# ESP32-H21 register map
Vendor: ESPRESSIF SYSTEMS (SHANGHAI) CO., LTD.; Series: ESP32 H-Series; File version: 1
CPU: RV32IMAC r0p0, little endian, no MPU, no FPU, 0 interrupt priority bits
Address unit: 32 bits
Registers are 32-bit, read-write, reset 0x0 unless marked. A register's access mark holds for its fields unless they carry their own. Offsets are from the block's base; [hi:lo] are bit positions; {n}, {i} and the like mark numbered series.

## LP_AON — LP_AON Peripheral
Base 0x600B1000
{0x0+4i} STORE{i} (i=0..9) — need_des
  [31:0] LP_AON_STORE{i}
0x28 GPIO_MUX — need_des
  [7:0] SEL
0x2C GPIO_HOLD0 — need_des
0x30 GPIO_HOLD1 — need_des
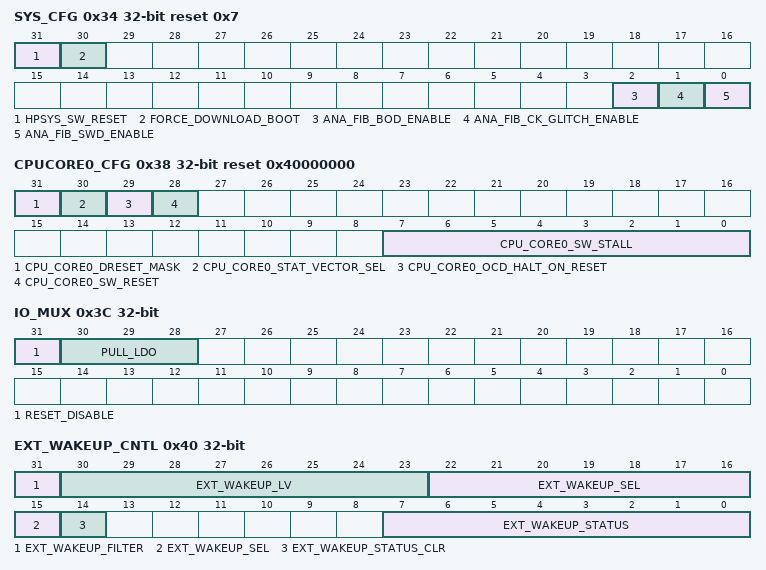
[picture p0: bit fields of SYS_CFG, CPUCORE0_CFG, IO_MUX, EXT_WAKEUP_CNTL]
0x34 SYS_CFG access per field reset 0x7 — need_des
  [31] HPSYS_SW_RESET wo — need_des
  [30] FORCE_DOWNLOAD_BOOT rw — need_des
  [2] ANA_FIB_BOD_ENABLE ro — need_des
  [1] ANA_FIB_CK_GLITCH_ENABLE ro — need_des
  [0] ANA_FIB_SWD_ENABLE ro — need_des
0x38 CPUCORE0_CFG access per field reset 0x40000000 — need_des
  [31] CPU_CORE0_DRESET_MASK rw — need_des
  [30] CPU_CORE0_STAT_VECTOR_SEL rw — need_des
  [29] CPU_CORE0_OCD_HALT_ON_RESET rw — need_des
  [28] CPU_CORE0_SW_RESET wo — need_des
  [7:0] CPU_CORE0_SW_STALL rw — need_des
0x3C IO_MUX — need_des
  [31] RESET_DISABLE — need_des
  [30:28] PULL_LDO — need_des
0x40 EXT_WAKEUP_CNTL access per field — need_des
  [31] EXT_WAKEUP_FILTER rw — need_des
  [30:23] EXT_WAKEUP_LV rw — need_des
  [22:15] EXT_WAKEUP_SEL rw — need_des
  [14] EXT_WAKEUP_STATUS_CLR wo — need_des
  [7:0] EXT_WAKEUP_STATUS ro — need_des
0x44 USB — need_des
  [31] RESET_DISABLE
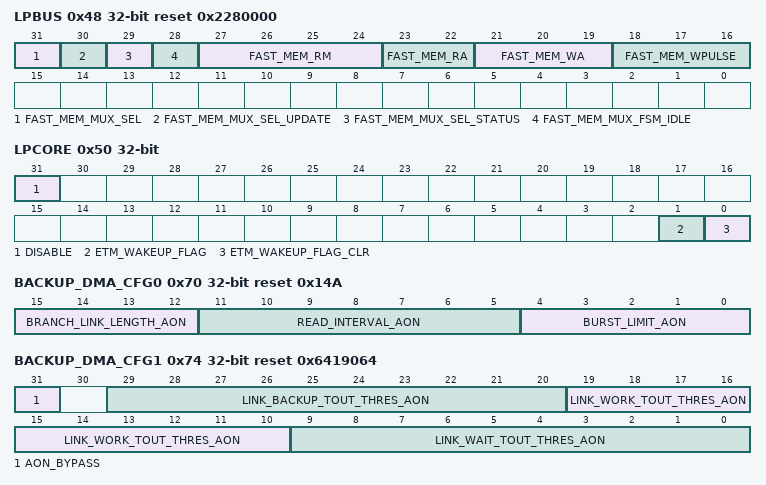
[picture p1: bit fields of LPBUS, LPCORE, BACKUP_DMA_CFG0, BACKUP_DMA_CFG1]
0x48 LPBUS access per field reset 0x2280000 — need_des
  [31] FAST_MEM_MUX_SEL ro — reserved
  [30] FAST_MEM_MUX_SEL_UPDATE ro — reserved
  [29] FAST_MEM_MUX_SEL_STATUS ro — reserved
  [28] FAST_MEM_MUX_FSM_IDLE ro — reserved
  [27:24] FAST_MEM_RM rw — This field controls fast memory RM parameter. 0b0011 for 1.1V operating Voltage, 0b0010 for 1.0V, 0b0000 for 0.9V.
  [23:22] FAST_MEM_RA rw — This field controls fast memory RA parameter. 0b00 for 1.1V/1.0V operating Voltage, 0b01 for 0.9V.
  [21:19] FAST_MEM_WA rw — This field controls fast memory WA parameter. 0b100 for 1.1V operating Voltage, 0b101 for 1.0V, 0b110 for 0.9V.
  [18:16] FAST_MEM_WPULSE rw — This field controls fast memory WPULSE parameter. 0b000 for 1.1V/1.0V/0.9V operating Voltage.
0x4C SDIO_ACTIVE reset 0x2800000 — need_des
  [31:22] SDIO_ACT_DNUM
0x50 LPCORE access per field — need_des
  [31] DISABLE rw — need_des
  [1] ETM_WAKEUP_FLAG rw — need_des
  [0] ETM_WAKEUP_FLAG_CLR wo — need_des
0x54 SAR_CCT — need_des
  [31:29] SAR2_PWDET_CCT
0x58 JTAG_SEL reset 0x80000000 — need_des
  [31] SOFT — If strapping_sel_jtag feature is disabled by efuse, and if neither pad_jtag or usb_jtag is disabled by efuse, this field determines which one jtag between usb_jtag and pad_jtag will be used. 1'b1(default): usb_jtag, 1'b0: pad_jtag.
0x70 BACKUP_DMA_CFG0 reset 0x14A — configure regdma always on register
  [15:12] BRANCH_LINK_LENGTH_AON — Set this field to configure link address.
  [11:5] READ_INTERVAL_AON — Set this field to configure read registers' interval time in reading mode.
  [4:0] BURST_LIMIT_AON — Set this field to configure max value of burst in signle transfer.
0x74 BACKUP_DMA_CFG1 reset 0x6419064 — configure regdma always on register
  [31] AON_BYPASS — reserved
  [29:20] LINK_BACKUP_TOUT_THRES_AON — Set this field to configure maximum waiting time in backup mode.
  [19:10] LINK_WORK_TOUT_THRES_AON — Set this field to configure maximum waiting time in waiting mode.
  [9:0] LINK_WAIT_TOUT_THRES_AON — Set this field to configure the number of consecutive links of link list.
0x78 BACKUP_DMA_CFG2 — configure regdma always on register
  [31:0] LINK_ADDR_AON — Set this field to configure link address.
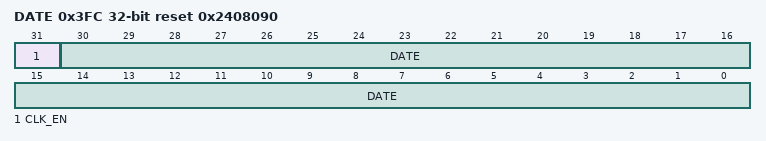
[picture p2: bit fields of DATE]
0x3FC DATE reset 0x2408090 — need_des
  [31] CLK_EN — need_des
  [30:0] DATE — need_des

## LP_APM — Low-power Access Permission Management Controller
Base 0x600B3800
0x00 REGION_FILTER_EN reset 0x1 — Region filter enable register
  [1:0] REGION_FILTER_EN — Region filter enable
0x04 REGION0_ADDR_START — Region address register
  [31:0] REGION0_ADDR_START — Start address of region0
0x08 REGION0_ADDR_END reset 0xFFFFFFFF — Region address register
  [31:0] REGION0_ADDR_END — End address of region0
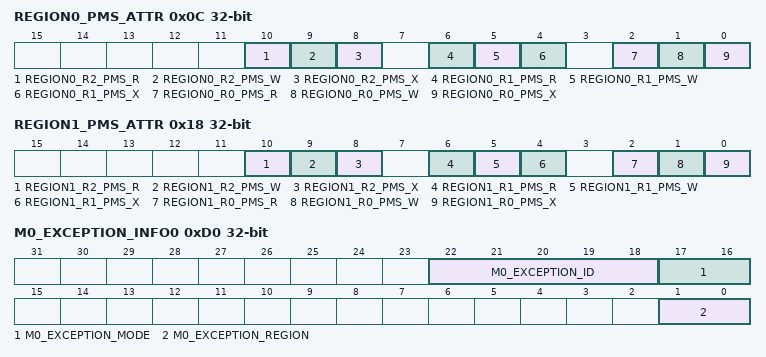
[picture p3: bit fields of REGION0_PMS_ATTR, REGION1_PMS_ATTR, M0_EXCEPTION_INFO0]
0x0C REGION0_PMS_ATTR — Region access authority attribute register
  [10] REGION0_R2_PMS_R — Region read authority in REE_MODE2
  [9] REGION0_R2_PMS_W — Region write authority in REE_MODE2
  [8] REGION0_R2_PMS_X — Region execute authority in REE_MODE2
  [6] REGION0_R1_PMS_R — Region read authority in REE_MODE1
  [5] REGION0_R1_PMS_W — Region write authority in REE_MODE1
  [4] REGION0_R1_PMS_X — Region execute authority in REE_MODE1
  [2] REGION0_R0_PMS_R — Region read authority in REE_MODE0
  [1] REGION0_R0_PMS_W — Region write authority in REE_MODE0
  [0] REGION0_R0_PMS_X — Region execute authority in REE_MODE0
0x10 REGION1_ADDR_START — Region address register
  [31:0] REGION1_ADDR_START — Start address of region1
0x14 REGION1_ADDR_END reset 0xFFFFFFFF — Region address register
  [31:0] REGION1_ADDR_END — End address of region1
0x18 REGION1_PMS_ATTR — Region access authority attribute register
  [10] REGION1_R2_PMS_R — Region read authority in REE_MODE2
  [9] REGION1_R2_PMS_W — Region write authority in REE_MODE2
  [8] REGION1_R2_PMS_X — Region execute authority in REE_MODE2
  [6] REGION1_R1_PMS_R — Region read authority in REE_MODE1
  [5] REGION1_R1_PMS_W — Region write authority in REE_MODE1
  [4] REGION1_R1_PMS_X — Region execute authority in REE_MODE1
  [2] REGION1_R0_PMS_R — Region read authority in REE_MODE0
  [1] REGION1_R0_PMS_W — Region write authority in REE_MODE0
  [0] REGION1_R0_PMS_X — Region execute authority in REE_MODE0
0xC4 FUNC_CTRL reset 0x1 — PMS function control register
  [0] M0_PMS_FUNC_EN — PMS M0 function enable
0xC8 M0_STATUS ro
  [1:0] M0_EXCEPTION_STATUS — Exception status
0xCC M0_STATUS_CLR wo — M0 status clear register
  [0] M0_REGION_STATUS_CLR — Clear exception status
0xD0 M0_EXCEPTION_INFO0 ro
  [22:18] M0_EXCEPTION_ID — Exception id information
  [17:16] M0_EXCEPTION_MODE — Exception mode
  [1:0] M0_EXCEPTION_REGION — Exception region
0xD4 M0_EXCEPTION_INFO1 ro
  [31:0] M0_EXCEPTION_ADDR — Exception addr
0xE8 INT_EN — APM interrupt enable register
  [0] M0_APM_INT_EN — APM M0 interrupt enable
0xEC CLOCK_GATE reset 0x1 — clock gating register
  [0] CLK_EN — reg_clk_en
0xFC DATE reset 0x2207260 — Version register
  [27:0] DATE — reg_date
